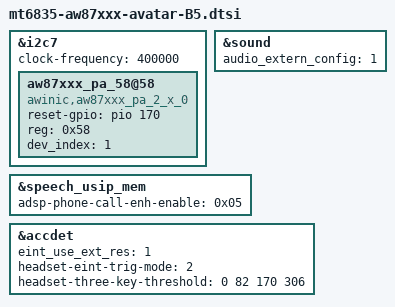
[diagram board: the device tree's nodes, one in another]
/* Copyright (c) 2018, The Linux Foundation. All rights reserved.
 *
 * This program is free software; you can redistribute it and/or modify
 * it under the terms of the GNU General Public License version 2 and
 * only version 2 as published by the Free Software Foundation.
 *
 * This program is distributed in the hope that it will be useful,
 * but WITHOUT ANY WARRANTY; without even the implied warranty of
 * MERCHANTABILITY or FITNESS FOR A PARTICULAR PURPOSE.  See the
 * GNU General Public License for more details.
 */


&i2c7 {
	clock-frequency = <400000>;

	aw87xxx_pa_58@58 {
		compatible = "awinic,aw87xxx_pa_2_x_0";
		reset-gpio = <&pio 170 0>;
		reg = <0x58>;
		dev_index = < 1 >;
		status = "okay";
	};

};

&sound {
	/* this dtsi config for product's special config, AudioHal read ctl 'OPLUS_AUDIO_EXTEN_CONFIG' get the values*
	 * 1st value --> PA type: 0:NXP Pa, 1:Awinic Pa 2:sia81xx Pa*/
	audio_extern_config = <1>;
};

&speech_usip_mem{
	adsp-phone-call-enh-enable = <0x05>;
};

&accdet{
	eint_use_ext_res = <1>;
	headset-eint-trig-mode = <2>;
	headset-three-key-threshold = <0 82 170 306>;
};
